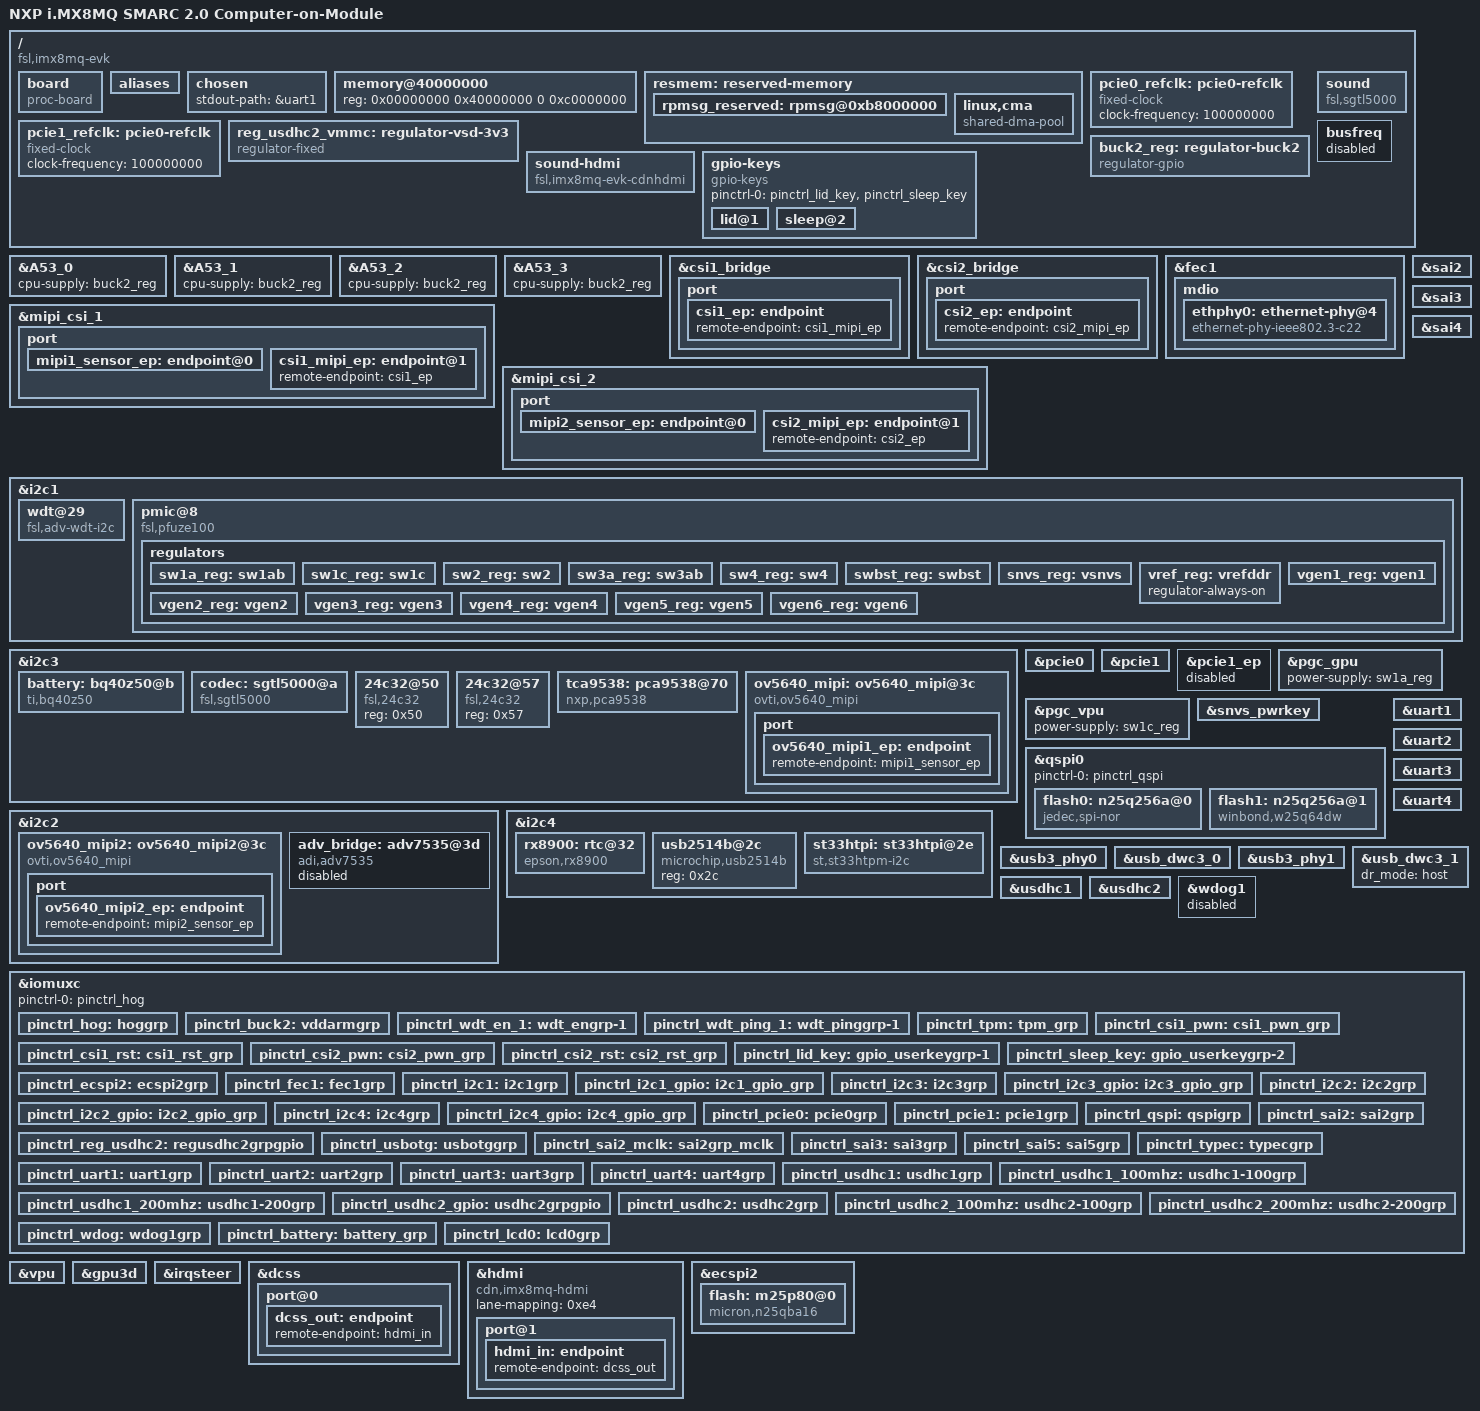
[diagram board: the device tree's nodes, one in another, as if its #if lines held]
// SPDX-License-Identifier: (GPL-2.0 OR MIT)
/*
 * Copyright 2017 NXP
 * Copyright (C) 2017-2018 Pengutronix, Lucas Stach <kernel@pengutronix.de>
 */

/dts-v1/;

//#define ENABLE_2ND_QSPI

#include <dt-bindings/usb/pd.h>
#include "imx8mq.dtsi"

/ {
	model = "NXP i.MX8MQ SMARC 2.0 Computer-on-Module";
	compatible = "fsl,imx8mq-evk", "fsl,imx8mq";

	board {
		compatible = "proc-board";
		board-type = "ROM-5720 A1";
		board-cpu = "IMX8MQ";
	};

	aliases {
		rtc0 = &rx8900;
		rtc1 = &snvs_rtc;
		sai0 = &sai1;
		sai1 = &sai2;
		sai2 = &sai3;
		sai3 = &sai4;
	};

	chosen {
		stdout-path = &uart1;
	};

	memory@40000000 {
		device_type = "memory";
		reg = <0x00000000 0x40000000 0 0xc0000000>;
	};

	reserved-memory {
		#address-cells = <2>;
		#size-cells = <2>;
		ranges;

		rpmsg_reserved: rpmsg@0xb8000000 {
			no-map;
			reg = <0 0xb8000000 0 0x400000>;
		};
	};



	resmem: reserved-memory {
		#address-cells = <2>;
		#size-cells = <2>;
		ranges;

		/* global autoconfigured region for contiguous allocations */
		linux,cma {
			compatible = "shared-dma-pool";
			reusable;
			size = <0 0x3c000000>;
			alloc-ranges = <0 0x40000000 0 0x40000000>;
			linux,cma-default;
		};
	};

	pcie0_refclk: pcie0-refclk {
		compatible = "fixed-clock";
		#clock-cells = <0>;
		clock-frequency = <100000000>;
	};

	pcie1_refclk: pcie0-refclk {
		compatible = "fixed-clock";
		#clock-cells = <0>;
		clock-frequency = <100000000>;
	};


	reg_usdhc2_vmmc: regulator-vsd-3v3 {
		pinctrl-names = "default";
		pinctrl-0 = <&pinctrl_reg_usdhc2>;
		compatible = "regulator-fixed";
		regulator-name = "VSD_3V3";
		regulator-min-microvolt = <3300000>;
		regulator-max-microvolt = <3300000>;
		gpio = <&gpio2 19 GPIO_ACTIVE_HIGH>;
		off-on-delay-us = <20000>;
		enable-active-high;
	};

	buck2_reg: regulator-buck2 {
		pinctrl-names = "default";
		pinctrl-0 = <&pinctrl_buck2>;
		compatible = "regulator-gpio";
		regulator-name = "vdd_arm";
		regulator-min-microvolt = <900000>;
		regulator-max-microvolt = <1000000>;
		gpios = <&gpio1 13 GPIO_ACTIVE_HIGH>;
		states = <1000000 0x0
			  900000 0x1>;
	};

        sound {
                compatible = "fsl,sgtl5000",
                             "fsl,imx-audio-sgtl5000";
                model = "sgtl5000";
                codec-master;
                ssi-controller = <&sai2>;
                audio-codec = <&codec>;
                audio-routing =
                        "MIC_IN", "Mic Jack",
                        "Mic Jack", "Mic Bias",
                        "Headphone Jack", "HP_OUT";
                no-audmux;
        };

	sound-hdmi {
		compatible = "fsl,imx8mq-evk-cdnhdmi",
				"fsl,imx-audio-cdnhdmi";
		model = "imx-audio-hdmi";
		audio-cpu = <&sai4>;
		protocol = <1>;
		hdmi-out;
		constraint-rate = <44100>,
				<88200>,
				<176400>,
				<32000>,
				<48000>,
				<96000>,
				<192000>;
	};

	gpio-keys {
                compatible = "gpio-keys";
                #address-cells = <1>;
                #size-cells = <0>;
                pinctrl-0 = <&pinctrl_lid_key &pinctrl_sleep_key>;
                pinctrl-names = "default";
                lid@1 {
			label = "LID KEY";
			gpios = <&gpio3 20 0>; /* GPIO_ACTIVE_LOW:1 */
			linux,input-type = <1>; /* EV_KEY */
			linux,code = <116>;     /* KEY_POWER */
			wakeup-source;
			debounce-interval = <100>;
                };
                sleep@2 {
			label = "SLEEP KEY";
			gpios = <&gpio3 25 0>; /* GPIO_ACTIVE_LOW:1 */
			linux,input-type = <1>; /* EV_KEY */
			linux,code = <116>;     /* KEY_POWER */
			wakeup-source;
			debounce-interval = <100>;
                };
	};

        busfreq {
                status = "disabled";
        };

};



&A53_0 {
	cpu-supply = <&buck2_reg>;
};

&A53_1 {
	cpu-supply = <&buck2_reg>;
};

&A53_2 {
	cpu-supply = <&buck2_reg>;
};

&A53_3 {
	cpu-supply = <&buck2_reg>;
};

&csi1_bridge {
	fsl,mipi-mode;
	fsl,two-8bit-sensor-mode;
	status = "okay";

	port {
		csi1_ep: endpoint {
			remote-endpoint = <&csi1_mipi_ep>;
		};
	};
};

&csi2_bridge {
	fsl,mipi-mode;
	fsl,two-8bit-sensor-mode;
	status = "okay";

	port {
		csi2_ep: endpoint {
			remote-endpoint = <&csi2_mipi_ep>;
		};
	};
};

&fec1 {
	pinctrl-names = "default";
	pinctrl-0 = <&pinctrl_fec1>;
	phy-mode = "rgmii-id";
	phy-handle = <&ethphy0>;
	fsl,magic-packet;
	status = "okay";

	mdio {
		#address-cells = <1>;
		#size-cells = <0>;

		ethphy0: ethernet-phy@4 {
			compatible = "ethernet-phy-ieee802.3-c22";
			reg = <4>;
			at803x,eee-disabled;
		};
	};
};

&mipi_csi_1 {
	#address-cells = <1>;
	#size-cells = <0>;
	status = "okay";
	port {
		mipi1_sensor_ep: endpoint@0 {
			remote-endpoint = <&ov5640_mipi1_ep>;
			data-lanes = <1 2>;
			bus-type = <4>;
		};

		csi1_mipi_ep: endpoint@1 {
			remote-endpoint = <&csi1_ep>;
		};
	};
};

&mipi_csi_2 {
	#address-cells = <1>;
	#size-cells = <0>;
	status = "okay";
	port {
		mipi2_sensor_ep: endpoint@0 {
			remote-endpoint = <&ov5640_mipi2_ep>;
			data-lanes = <1 2>;
			bus-type = <4>;
		};

		csi2_mipi_ep: endpoint@1 {
			remote-endpoint = <&csi2_ep>;
		};
	};
};

&sai2 {
	pinctrl-names = "default";
	pinctrl-0 = <&pinctrl_sai2>;
	assigned-clocks = <&clk IMX8MQ_CLK_SAI2>;
	assigned-clock-parents = <&clk IMX8MQ_AUDIO_PLL1_OUT>;
	assigned-clock-rates = <24576000>;
	status = "okay";
};

&sai3 {
	#sound-dai-cells = <0>;
	pinctrl-names = "default";
	pinctrl-0 = <&pinctrl_sai3>;
	assigned-clocks = <&clk IMX8MQ_CLK_SAI3>;
	assigned-clock-parents = <&clk IMX8MQ_AUDIO_PLL1_OUT>;
	assigned-clock-rates = <24576000>;
	status = "okay";
};

&sai4 {
	assigned-clocks = <&clk IMX8MQ_CLK_SAI4>;
	assigned-clock-parents = <&clk IMX8MQ_AUDIO_PLL1_OUT>;
	assigned-clock-rates = <24576000>;
	clocks = <&clk IMX8MQ_CLK_SAI4_IPG>, <&clk IMX8MQ_CLK_DUMMY>,
		<&clk IMX8MQ_CLK_SAI4_ROOT>, <&clk IMX8MQ_CLK_DUMMY>,
		<&clk IMX8MQ_CLK_DUMMY>, <&clk IMX8MQ_AUDIO_PLL1_OUT>,
		<&clk IMX8MQ_AUDIO_PLL2_OUT>;
	clock-names = "bus", "mclk0", "mclk1", "mclk2", "mclk3", "pll8k", "pll11k";
	status = "okay";
};

&i2c1 {
	clock-frequency = <400000>;
	pinctrl-names = "default";
	pinctrl-0 = <&pinctrl_i2c1>;
	pinctrl-1 = <&pinctrl_i2c1_gpio>;
        scl-gpios = <&gpio5 14 GPIO_ACTIVE_HIGH>;
        sda-gpios = <&gpio5 15 GPIO_ACTIVE_HIGH>;
	status = "okay";

	wdt@29 {
                compatible = "fsl,adv-wdt-i2c";
                pinctrl-names = "default";
                pinctrl-0 = <&pinctrl_wdt_en_1 &pinctrl_wdt_ping_1>;
                status = "okay";
                wdt-en = <&gpio3 18 0>;
                wdt-ping = <&gpio4 22 0>;
                reg = <0x29>;
        };

	pmic@8 {
		compatible = "fsl,pfuze100";
		fsl,pfuze-support-disable-sw;
		reg = <0x8>;

		regulators {
			sw1a_reg: sw1ab {
				regulator-min-microvolt = <825000>;
				regulator-max-microvolt = <1100000>;
			};

			sw1c_reg: sw1c {
				regulator-min-microvolt = <825000>;
				regulator-max-microvolt = <1100000>;
			};

			sw2_reg: sw2 {
				regulator-min-microvolt = <1100000>;
				regulator-max-microvolt = <1100000>;
				regulator-always-on;
			};

			sw3a_reg: sw3ab {
				regulator-min-microvolt = <825000>;
				regulator-max-microvolt = <1100000>;
				regulator-always-on;
			};

			sw4_reg: sw4 {
				regulator-min-microvolt = <1800000>;
				regulator-max-microvolt = <1800000>;
				regulator-always-on;
			};

			swbst_reg: swbst {
				regulator-min-microvolt = <5000000>;
				regulator-max-microvolt = <5150000>;
			};

			snvs_reg: vsnvs {
				regulator-min-microvolt = <1000000>;
				regulator-max-microvolt = <3000000>;
				regulator-always-on;
			};

			vref_reg: vrefddr {
				regulator-always-on;
			};

			vgen1_reg: vgen1 {
				regulator-min-microvolt = <800000>;
				regulator-max-microvolt = <1550000>;
			};

			vgen2_reg: vgen2 {
				regulator-min-microvolt = <850000>;
				regulator-max-microvolt = <975000>;
				regulator-always-on;
			};

			vgen3_reg: vgen3 {
				regulator-min-microvolt = <1675000>;
				regulator-max-microvolt = <1975000>;
				regulator-always-on;
			};

			vgen4_reg: vgen4 {
				regulator-min-microvolt = <1625000>;
				regulator-max-microvolt = <1875000>;
				regulator-always-on;
			};

			vgen5_reg: vgen5 {
				regulator-min-microvolt = <3075000>;
				regulator-max-microvolt = <3625000>;
				regulator-always-on;
			};

			vgen6_reg: vgen6 {
				regulator-min-microvolt = <1800000>;
				regulator-max-microvolt = <3300000>;
			};
		};
	};

};

&i2c3 {
	clock-frequency = <100000>;
	pinctrl-names = "default";
	pinctrl-0 = <&pinctrl_i2c3>;
	pinctrl-1 = <&pinctrl_i2c3_gpio>;
        scl-gpios = <&gpio5 18 GPIO_ACTIVE_HIGH>;
        sda-gpios = <&gpio5 19 GPIO_ACTIVE_HIGH>;
	status = "okay";

        battery: bq40z50@b {
                compatible = "ti,bq40z50";
                reg = <0x0b>;
                pinctrl-names = "default";
                pinctrl-0 = <&pinctrl_battery>;
        };

	codec: sgtl5000@a {
		compatible = "fsl,sgtl5000";
		reg = <0x0a>;
                clocks = <&clk IMX8MQ_CLK_SAI2_ROOT>;
		clock-names = "mclk";
		pinctrl-names = "default";
                pinctrl-0 = <&pinctrl_sai2_mclk>;

	};
        24c32@50 {
                compatible = "fsl,24c32";
                reg = <0x50>;
        };
	
        24c32@57 {
                compatible = "fsl,24c32";
                reg = <0x57>;
        };
	tca9538: pca9538@70 {
		compatible = "nxp,pca9538";
		reg = <0x70>;
		#gpio-cells = <2>;
		gpio-controller;
	};
	ov5640_mipi: ov5640_mipi@3c {
                compatible = "ovti,ov5640_mipi";
                reg = <0x3c>;
                status = "okay";
                pinctrl-names = "default";
                pinctrl-0 = <&pinctrl_csi1_pwn>, <&pinctrl_csi1_rst>;
                clocks = <&clk IMX8MQ_CLK_CLKO1>;
                clock-names = "csi_mclk";
                assigned-clocks = <&clk IMX8MQ_CLK_CLKO1>;
                assigned-clock-parents = <&clk IMX8MQ_SYS2_PLL_200M>;
		assigned-clock-rates = <20000000>;                
                csi_id = <0>;
                pwn-gpios = <&gpio1 3 GPIO_ACTIVE_HIGH>;
                rst-gpios = <&gpio4 29 GPIO_ACTIVE_LOW>;
		mclk = <20000000>;
		mclk_source = <0>;
                port {
                        ov5640_mipi1_ep: endpoint {
                                remote-endpoint = <&mipi1_sensor_ep>;
                        };
                };
        };

};

&i2c2 {
	clock-frequency = <100000>;
	pinctrl-names = "default";
	pinctrl-0 = <&pinctrl_i2c2>;
        pinctrl-1 = <&pinctrl_i2c2_gpio>;
        scl-gpios = <&gpio5 16 GPIO_ACTIVE_HIGH>;
        sda-gpios = <&gpio5 17 GPIO_ACTIVE_HIGH>;
	status = "okay";

	ov5640_mipi2: ov5640_mipi2@3c {
		compatible = "ovti,ov5640_mipi";
		reg = <0x3c>;
		status = "okay";
		pinctrl-names = "default";
		pinctrl-0 = <&pinctrl_csi2_pwn>, <&pinctrl_csi2_rst>;
		clocks = <&clk IMX8MQ_CLK_CLKO1>;
		clock-names = "csi_mclk";
		assigned-clocks = <&clk IMX8MQ_CLK_CLKO1>;
		assigned-clock-parents = <&clk IMX8MQ_SYS2_PLL_200M>;
		assigned-clock-rates = <0>, <20000000>;  
		csi_id = <1>;
                pwn-gpios = <&gpio1 5 GPIO_ACTIVE_HIGH>;
                rst-gpios = <&gpio1 6 GPIO_ACTIVE_LOW>;
		mclk = <20000000>;
		mclk_source = <0>;
		port {
			ov5640_mipi2_ep: endpoint {
				remote-endpoint = <&mipi2_sensor_ep>;
			};
		};
	};
        adv_bridge: adv7535@3d {
                compatible = "adi,adv7535";
                reg = <0x3d>;
                pinctrl-names = "default";
                pinctrl-0 = <&pinctrl_lcd0>;
		pd-gpios = <&gpio5 6 1>;
                adi,addr-cec = <0x3b>;
                adi,dsi-lanes = <4>;
                interrupt-parent = <&gpio5>;
                interrupts = <7 IRQ_TYPE_LEVEL_LOW>;
                status = "disabled";
        };

};

&i2c4 {
	clock-frequency = <100000>;
        pinctrl-names = "default", "gpio";
        pinctrl-0 = <&pinctrl_i2c4>;
        pinctrl-1 = <&pinctrl_i2c4_gpio>;
        scl-gpios = <&gpio5 20 GPIO_ACTIVE_HIGH>;
        sda-gpios = <&gpio5 21 GPIO_ACTIVE_HIGH>;
	status = "okay";

	rx8900: rtc@32 {
		compatible = "epson,rx8900";
		reg = <0x32>;
                epson,vdet-disable;
                trickle-diode-disable;
	};


        usb2514b@2c {
                compatible = "microchip,usb2514b";
                reg = <0x2c>;
        };
	
	st33htpi: st33htpi@2e{
		compatible = "st,st33htpm-i2c";
		reg= <0x2e>;
		pinctrl-names = "default";
                pinctrl-0 = <&pinctrl_tpm>;
                interrupt-parent = <&gpio5>;
                interrupts = <5 IRQ_TYPE_LEVEL_HIGH>;
	};

};

&pcie0 {
	pinctrl-names = "default";
	pinctrl-0 = <&pinctrl_pcie0>;
        reset-gpio = <&gpio4 11 GPIO_ACTIVE_LOW>;
	clocks = <&clk IMX8MQ_CLK_PCIE1_ROOT>,
		 <&clk IMX8MQ_CLK_PCIE1_AUX>,
		 <&clk IMX8MQ_CLK_PCIE1_PHY>,
		 <&pcie0_refclk>;
	clock-names = "pcie", "pcie_aux", "pcie_phy", "pcie_bus";
	ext_osc = <1>;
	status = "okay";
};

&pcie1 {
	pinctrl-names = "default";
	pinctrl-0 = <&pinctrl_pcie1>;
	reset-gpio = <&gpio4 10 GPIO_ACTIVE_LOW>;
	clocks = <&clk IMX8MQ_CLK_PCIE2_ROOT>,
		 <&clk IMX8MQ_CLK_PCIE2_AUX>,
		 <&clk IMX8MQ_CLK_PCIE2_PHY>,
		 <&pcie1_refclk>;
	clock-names = "pcie", "pcie_aux", "pcie_phy", "pcie_bus";
	reset-gpio = <&gpio4 10 GPIO_ACTIVE_LOW>;
	//disable-gpio = <&tca9538 0 GPIO_ACTIVE_LOW>; //W_DISABLE1
	status = "okay";
};

&pcie1_ep {
	pinctrl-names = "default";
	pinctrl-0 = <&pinctrl_pcie1>;
	clocks = <&clk IMX8MQ_CLK_PCIE2_ROOT>,
		 <&clk IMX8MQ_CLK_PCIE2_AUX>,
		 <&clk IMX8MQ_CLK_PCIE2_PHY>,
		 <&pcie1_refclk>;
	clock-names = "pcie", "pcie_aux", "pcie_phy", "pcie_bus";
	status = "disabled";
};

&pgc_gpu {
	power-supply = <&sw1a_reg>;
};

&pgc_vpu {
	power-supply = <&sw1c_reg>;
};

&snvs_pwrkey {
	status = "okay";
};

&qspi0 {
	pinctrl-names = "default";
	pinctrl-0 = <&pinctrl_qspi>;
	status = "okay";
/*
        fsl,qspi-has-second-chip = <1>;
*/
//        ddrsmp=<0>;
	flash0: n25q256a@0 {
		reg = <0>;
		#address-cells = <1>;
		#size-cells = <1>;
		compatible = "jedec,spi-nor";
		spi-max-frequency = <29000000>;
		spi-tx-bus-width = <4>;
		spi-rx-bus-width = <4>;
		spi-nor,ddr-quad-read-dummy = <6>;
	};
#ifdef ENABLE_2ND_QSPI
	flash1: n25q256a@1 {
		reg = <1>;
		#address-cells = <1>;
		#size-cells = <1>;
		compatible = "winbond,w25q64dw";
		spi-max-frequency = <29000000>;
		spi-nor,ddr-quad-read-dummy = <6>;
	};
#endif
};

&uart1 {
	pinctrl-names = "default";
	pinctrl-0 = <&pinctrl_uart1>;
	assigned-clocks = <&clk IMX8MQ_CLK_UART1>;
	assigned-clock-parents = <&clk IMX8MQ_CLK_25M>;
	status = "okay";
};

&uart2 {
	pinctrl-names = "default";
	pinctrl-0 = <&pinctrl_uart2>;
	assigned-clocks = <&clk IMX8MQ_CLK_UART2>;
	assigned-clock-parents = <&clk IMX8MQ_CLK_25M>;
	status = "okay";
};

&uart3 { /* BT */
	pinctrl-names = "default";
	pinctrl-0 = <&pinctrl_uart3>;
	assigned-clocks = <&clk IMX8MQ_CLK_UART3>;
	assigned-clock-parents = <&clk IMX8MQ_CLK_25M>;
	fsl,uart-has-rtscts;
	status = "okay";
};

&uart4 {
	pinctrl-names = "default";
	pinctrl-0 = <&pinctrl_uart4>;
	assigned-clocks = <&clk IMX8MQ_CLK_UART4>;
	assigned-clock-parents = <&clk IMX8MQ_CLK_25M>;
	status = "okay";
};

&usb3_phy0 {
	status = "okay";
};

&usb_dwc3_0 {
	pinctrl-names = "default";
	pinctrl-0 = <&pinctrl_usbotg>;
	dr_mode = "host";

	status = "okay";
};

&usb3_phy1 {
	status = "okay";
};

&usb_dwc3_1 {
	dr_mode = "host";
	status = "okay";
};

&usdhc1 {
	pinctrl-names = "default";
	pinctrl-0 = <&pinctrl_usdhc1>;
	vqmmc-supply = <&sw4_reg>;
	bus-width = <8>;
	non-removable;
	no-sd;
	no-sdio;
	status = "okay";
};

&usdhc2 {
	pinctrl-names = "default";
	pinctrl-0 = <&pinctrl_usdhc2>, <&pinctrl_usdhc2_gpio>;
	cd-gpios = <&gpio2 12 GPIO_ACTIVE_LOW>;
	wp-gpios = <&gpio2 20 GPIO_ACTIVE_HIGH>;
	vmmc-supply = <&reg_usdhc2_vmmc>;
	status = "okay";
};

&wdog1 {
	pinctrl-names = "default";
	pinctrl-0 = <&pinctrl_wdog>;
	fsl,ext-reset-output;
	status = "disabled";
};

&iomuxc {
	pinctrl-names = "default";
	pinctrl-0 = <&pinctrl_hog>;

	pinctrl_hog: hoggrp {
		fsl,pins = <
			MX8MQ_IOMUXC_GPIO1_IO00_GPIO1_IO0		0x19	/* GPIO4 */
			MX8MQ_IOMUXC_SPDIF_RX_GPIO5_IO4			0x19	/* GPIO5 */
			MX8MQ_IOMUXC_SAI5_RXFS_GPIO3_IO19		0x19	/* GPIO6 */
			MX8MQ_IOMUXC_SAI5_RXD0_GPIO3_IO21		0x19	/* GPIO7 */
			MX8MQ_IOMUXC_GPIO1_IO08_GPIO1_IO8		0x19	/* GPIO8 */
			MX8MQ_IOMUXC_SAI5_RXD2_GPIO3_IO23		0x19	/* GPIO9 */
			MX8MQ_IOMUXC_SAI3_RXFS_GPIO4_IO28		0x19	/* GPIO10 */	
			MX8MQ_IOMUXC_SAI1_RXFS_GPIO4_IO0		0x19	/* GPIO11 */
			MX8MQ_IOMUXC_GPIO1_IO12_GPIO1_IO12		0x19	/* USB1_OTG_VBUS */
			MX8MQ_IOMUXC_GPIO1_IO14_CCMSRCGPCMIX_CLKO1	0x59	/* CAM_MCK */
			MX8MQ_IOMUXC_SAI5_RXD1_GPIO3_IO22		0x19	/* TEST */
			MX8MQ_IOMUXC_SAI1_MCLK_GPIO4_IO20		0x19	/* UART_DBG_SEL */
			MX8MQ_IOMUXC_NAND_CE1_B_GPIO3_IO2		0x19	/* RESET_DELAY */
		>;
	};

	pinctrl_buck2: vddarmgrp {
		fsl,pins = <
			MX8MQ_IOMUXC_GPIO1_IO13_GPIO1_IO13		0x19
		>;

	};


	pinctrl_wdt_en_1: wdt_engrp-1 {
		fsl,pins = <
			MX8MQ_IOMUXC_NAND_WP_B_GPIO3_IO18		0x19	/* WDT_EN */
		>;
	};
	pinctrl_wdt_ping_1: wdt_pinggrp-1 {
		fsl,pins = <
			MX8MQ_IOMUXC_SAI2_RXC_GPIO4_IO22		0x19	/* WDOG_TRIG */
			>;
	};

	pinctrl_tpm: tpm_grp {
		fsl,pins = <
			MX8MQ_IOMUXC_SAI1_RXC_GPIO4_IO1			0x19	/* TPM_RESET */
			MX8MQ_IOMUXC_SPDIF_EXT_CLK_GPIO5_IO5		0x19	/* TPM_IRQ */
		>;
	};

	pinctrl_csi1_pwn: csi1_pwn_grp {
		fsl,pins = <
			MX8MQ_IOMUXC_GPIO1_IO03_GPIO1_IO3		0x19	/* GPIO0 or CAM0_PWR*/
		>;
	};

        pinctrl_csi1_rst: csi1_rst_grp {
                fsl,pins = <
			MX8MQ_IOMUXC_SAI3_RXC_GPIO4_IO29		0x19	/* GPIO2 or CAM0_RST*/
                >;
        };

	pinctrl_csi2_pwn: csi2_pwn_grp {
		fsl,pins = <
			MX8MQ_IOMUXC_GPIO1_IO05_GPIO1_IO5               0x19	/* GPIO1 or CAM1_PWR*/
		>;
	};

        pinctrl_csi2_rst: csi2_rst_grp {
                fsl,pins = <
                        MX8MQ_IOMUXC_GPIO1_IO06_GPIO1_IO6               0x19	/* GPIO3 or CAM1_RST*/
                >;
        };

	pinctrl_lid_key: gpio_userkeygrp-1 {
		fsl,pins = <
			MX8MQ_IOMUXC_SAI5_RXC_GPIO3_IO20		0x59	/* LID */
		>;
	};
	pinctrl_sleep_key: gpio_userkeygrp-2 {
		fsl,pins = <
			MX8MQ_IOMUXC_SAI5_MCLK_GPIO3_IO25		0x59	/* SLEEP */	
		>;
	};

        pinctrl_ecspi2: ecspi2grp {
                fsl,pins = <
			MX8MQ_IOMUXC_ECSPI2_SS0_GPIO5_IO13		0x19	/* SPI0_CS0 */
			MX8MQ_IOMUXC_ECSPI2_MOSI_ECSPI2_MOSI		0x82	/* SPI0_DO */
			MX8MQ_IOMUXC_ECSPI2_MISO_ECSPI2_MISO		0x82	/* SPI0_DIN */
			MX8MQ_IOMUXC_ECSPI2_SCLK_ECSPI2_SCLK		0x82	/* SPI0_CK */
                >;
        };

	pinctrl_fec1: fec1grp {
		fsl,pins = <
			MX8MQ_IOMUXC_ENET_MDC_ENET1_MDC			0x3
			MX8MQ_IOMUXC_ENET_MDIO_ENET1_MDIO		0x23
			MX8MQ_IOMUXC_ENET_TD3_ENET1_RGMII_TD3		0x1f
			MX8MQ_IOMUXC_ENET_TD2_ENET1_RGMII_TD2		0x1f
			MX8MQ_IOMUXC_ENET_TD1_ENET1_RGMII_TD1		0x1f
			MX8MQ_IOMUXC_ENET_TD0_ENET1_RGMII_TD0		0x1f
			MX8MQ_IOMUXC_ENET_RD3_ENET1_RGMII_RD3		0x91
			MX8MQ_IOMUXC_ENET_RD2_ENET1_RGMII_RD2		0x91
			MX8MQ_IOMUXC_ENET_RD1_ENET1_RGMII_RD1		0x91
			MX8MQ_IOMUXC_ENET_RD0_ENET1_RGMII_RD0		0x91
			MX8MQ_IOMUXC_ENET_TXC_ENET1_RGMII_TXC		0x1f
			MX8MQ_IOMUXC_ENET_RXC_ENET1_RGMII_RXC		0x91
			MX8MQ_IOMUXC_ENET_RX_CTL_ENET1_RGMII_RX_CTL	0x91
			MX8MQ_IOMUXC_ENET_TX_CTL_ENET1_RGMII_TX_CTL	0x1f
			MX8MQ_IOMUXC_GPIO1_IO09_GPIO1_IO9		0x19
		>;
	};

	pinctrl_i2c1: i2c1grp {
		fsl,pins = <
			MX8MQ_IOMUXC_I2C1_SCL_I2C1_SCL			0x4000007f
			MX8MQ_IOMUXC_I2C1_SDA_I2C1_SDA			0x4000007f
		>;
	};

        pinctrl_i2c1_gpio: i2c1_gpio_grp {
                fsl,pins = <
                        MX8MQ_IOMUXC_I2C1_SCL_GPIO5_IO14                0x19
                        MX8MQ_IOMUXC_I2C1_SDA_GPIO5_IO15                0x19
                >;
        };

	pinctrl_i2c3: i2c3grp {
		fsl,pins = <
			MX8MQ_IOMUXC_I2C3_SCL_I2C3_SCL			0x4000007f
			MX8MQ_IOMUXC_I2C3_SDA_I2C3_SDA			0x4000007f
		>;
	};

        pinctrl_i2c3_gpio: i2c3_gpio_grp {
                fsl,pins = <
                        MX8MQ_IOMUXC_I2C3_SCL_GPIO5_IO18                0x19
                        MX8MQ_IOMUXC_I2C3_SDA_GPIO5_IO19                0x19
                >;
        };

	pinctrl_i2c2: i2c2grp {
		fsl,pins = <
			MX8MQ_IOMUXC_I2C2_SCL_I2C2_SCL			0x40000067
			MX8MQ_IOMUXC_I2C2_SDA_I2C2_SDA			0x40000067
		>;
	};

        pinctrl_i2c2_gpio: i2c2_gpio_grp {
                fsl,pins = <
                        MX8MQ_IOMUXC_I2C2_SCL_GPIO5_IO16                0x19
                        MX8MQ_IOMUXC_I2C2_SDA_GPIO5_IO17                0x19
                >;
        };

	pinctrl_i2c4: i2c4grp {
		fsl,pins = <
			MX8MQ_IOMUXC_I2C4_SCL_I2C4_SCL			0x40000067
			MX8MQ_IOMUXC_I2C4_SDA_I2C4_SDA			0x40000067
		>;
	};

        pinctrl_i2c4_gpio: i2c4_gpio_grp {
                fsl,pins = <
                        MX8MQ_IOMUXC_I2C4_SCL_GPIO5_IO20                0x19
                        MX8MQ_IOMUXC_I2C4_SDA_GPIO5_IO21                0x19
                >;
        };

        pinctrl_pcie0: pcie0grp {
                fsl,pins = <
                        MX8MQ_IOMUXC_SAI1_TXC_GPIO4_IO11	0x16	/* PCIE_B_RST */
                >;
        };


        pinctrl_pcie1: pcie1grp {
                fsl,pins = <
                        MX8MQ_IOMUXC_SAI1_TXFS_GPIO4_IO10       0x16	/* PCIE_A_RST */
                >;
        };


	pinctrl_qspi: qspigrp {
		fsl,pins = <
			MX8MQ_IOMUXC_NAND_ALE_QSPI_A_SCLK	0x82
			MX8MQ_IOMUXC_NAND_CE0_B_QSPI_A_SS0_B	0x82
			MX8MQ_IOMUXC_NAND_DATA00_QSPI_A_DATA0	0x82
			MX8MQ_IOMUXC_NAND_DATA01_QSPI_A_DATA1	0x82
			MX8MQ_IOMUXC_NAND_DATA02_QSPI_A_DATA2	0x82
			MX8MQ_IOMUXC_NAND_DATA03_QSPI_A_DATA3	0x82
#ifdef ENABLE_2ND_QSPI
                        MX8MQ_IOMUXC_NAND_CLE_QSPI_B_SCLK       0x82
			MX8MQ_IOMUXC_NAND_CE3_B_QSPI_B_SS1_B	0x82 
                        MX8MQ_IOMUXC_NAND_CE2_B_QSPI_B_SS0_B    0x82
                        MX8MQ_IOMUXC_NAND_DATA04_QSPI_B_DATA0   0x82
                        MX8MQ_IOMUXC_NAND_DATA05_QSPI_B_DATA1   0x82
                        MX8MQ_IOMUXC_NAND_DATA06_QSPI_B_DATA2   0x82
                        MX8MQ_IOMUXC_NAND_DATA07_QSPI_B_DATA3   0x82
#endif
		>;
	};

	pinctrl_reg_usdhc2: regusdhc2grpgpio {
		fsl,pins = <
			MX8MQ_IOMUXC_SD2_RESET_B_GPIO2_IO19		0x41
		>;
	};

        pinctrl_usbotg: usbotggrp {
                fsl,pins = <
			MX8MQ_IOMUXC_GPIO1_IO10_GPIO1_IO10	0x19	/* USB0_OTG_ID_1V8*/
			MX8MQ_IOMUXC_SAI2_RXFS_GPIO4_IO21	0x16	/* USB_OTG0_OC */
                >;
        };

	pinctrl_sai2: sai2grp {
		fsl,pins = <
			MX8MQ_IOMUXC_SAI2_TXFS_SAI2_TX_SYNC	0xd6	/* I2S0_LRCK */
			MX8MQ_IOMUXC_SAI2_TXC_SAI2_TX_BCLK	0xd6	/* I2S0_CK */
			MX8MQ_IOMUXC_SAI2_RXD0_SAI2_RX_DATA0	0xd6	/* I2S0_SDIN */
			MX8MQ_IOMUXC_SAI2_TXD0_SAI2_TX_DATA0	0xd6	/* I2S0_SDOUT */
		>;
	};

        pinctrl_sai2_mclk: sai2grp_mclk {
                fsl,pins = <
			MX8MQ_IOMUXC_SAI2_MCLK_SAI2_MCLK        0xd6	/* AUDIO_MCK */
                >;
        };
	
	pinctrl_sai3: sai3grp {
		fsl,pins = <
			MX8MQ_IOMUXC_SAI3_TXFS_SAI3_TX_SYNC     0xd6
			MX8MQ_IOMUXC_SAI3_TXC_SAI3_TX_BCLK      0xd6
			MX8MQ_IOMUXC_SAI3_TXD_SAI3_TX_DATA0	0xd6
			MX8MQ_IOMUXC_SAI3_RXD_SAI3_RX_DATA0	0xd6
		>;
	};

	pinctrl_sai5: sai5grp {
		fsl,pins = <
			MX8MQ_IOMUXC_SAI5_MCLK_SAI5_MCLK	0xd6
			MX8MQ_IOMUXC_SAI5_RXC_SAI5_RX_BCLK	0xd6
			MX8MQ_IOMUXC_SAI5_RXFS_SAI5_RX_SYNC	0xd6
			MX8MQ_IOMUXC_SAI5_RXD0_SAI5_RX_DATA0	0xd6
			MX8MQ_IOMUXC_SAI5_RXD1_SAI5_RX_DATA1    0xd6
			MX8MQ_IOMUXC_SAI5_RXD2_SAI5_RX_DATA2    0xd6
			MX8MQ_IOMUXC_SAI5_RXD3_SAI5_RX_DATA3    0xd6
		>;
	};


	pinctrl_typec: typecgrp {
		fsl,pins = <
			MX8MQ_IOMUXC_NAND_CE2_B_GPIO3_IO3		0x17059
		>;
	};

	pinctrl_uart1: uart1grp {
		fsl,pins = <
			MX8MQ_IOMUXC_UART1_RXD_UART1_DCE_RX		0x49
			MX8MQ_IOMUXC_UART1_TXD_UART1_DCE_TX		0x49
		>;
	};

	pinctrl_uart2: uart2grp {
		fsl,pins = <
			MX8MQ_IOMUXC_UART2_RXD_UART2_DCE_RX		0x49
			MX8MQ_IOMUXC_UART2_TXD_UART2_DCE_TX		0x49
		>;
	};

	pinctrl_uart3: uart3grp {
		fsl,pins = <
			MX8MQ_IOMUXC_UART3_TXD_UART3_DCE_TX		0x49
			MX8MQ_IOMUXC_UART3_RXD_UART3_DCE_RX		0x49
			MX8MQ_IOMUXC_ECSPI1_MISO_UART3_DCE_CTS_B	0x49
			MX8MQ_IOMUXC_ECSPI1_SS0_UART3_DCE_RTS_B		0x49
		>;
	};

	pinctrl_uart4: uart4grp {
		fsl,pins = <
			MX8MQ_IOMUXC_UART4_RXD_UART4_DCE_RX		0x49
			MX8MQ_IOMUXC_UART4_TXD_UART4_DCE_TX		0x49
		>;
	};

	pinctrl_usdhc1: usdhc1grp {
		fsl,pins = <
			MX8MQ_IOMUXC_SD1_CLK_USDHC1_CLK			0x83
			MX8MQ_IOMUXC_SD1_CMD_USDHC1_CMD			0xc3
			MX8MQ_IOMUXC_SD1_DATA0_USDHC1_DATA0		0xc3
			MX8MQ_IOMUXC_SD1_DATA1_USDHC1_DATA1		0xc3
			MX8MQ_IOMUXC_SD1_DATA2_USDHC1_DATA2		0xc3
			MX8MQ_IOMUXC_SD1_DATA3_USDHC1_DATA3		0xc3
			MX8MQ_IOMUXC_SD1_DATA4_USDHC1_DATA4		0xc3
			MX8MQ_IOMUXC_SD1_DATA5_USDHC1_DATA5		0xc3
			MX8MQ_IOMUXC_SD1_DATA6_USDHC1_DATA6		0xc3
			MX8MQ_IOMUXC_SD1_DATA7_USDHC1_DATA7		0xc3
			MX8MQ_IOMUXC_SD1_STROBE_USDHC1_STROBE		0x83
			MX8MQ_IOMUXC_SD1_RESET_B_USDHC1_RESET_B		0xc1
		>;
	};

	pinctrl_usdhc1_100mhz: usdhc1-100grp {
		fsl,pins = <
			MX8MQ_IOMUXC_SD1_CLK_USDHC1_CLK			0x8d
			MX8MQ_IOMUXC_SD1_CMD_USDHC1_CMD			0xcd
			MX8MQ_IOMUXC_SD1_DATA0_USDHC1_DATA0		0xcd
			MX8MQ_IOMUXC_SD1_DATA1_USDHC1_DATA1		0xcd
			MX8MQ_IOMUXC_SD1_DATA2_USDHC1_DATA2		0xcd
			MX8MQ_IOMUXC_SD1_DATA3_USDHC1_DATA3		0xcd
			MX8MQ_IOMUXC_SD1_DATA4_USDHC1_DATA4		0xcd
			MX8MQ_IOMUXC_SD1_DATA5_USDHC1_DATA5		0xcd
			MX8MQ_IOMUXC_SD1_DATA6_USDHC1_DATA6		0xcd
			MX8MQ_IOMUXC_SD1_DATA7_USDHC1_DATA7		0xcd
			MX8MQ_IOMUXC_SD1_STROBE_USDHC1_STROBE		0x8d
			MX8MQ_IOMUXC_SD1_RESET_B_USDHC1_RESET_B		0xc1
		>;
	};

	pinctrl_usdhc1_200mhz: usdhc1-200grp {
		fsl,pins = <
			MX8MQ_IOMUXC_SD1_CLK_USDHC1_CLK			0x9f
			MX8MQ_IOMUXC_SD1_CMD_USDHC1_CMD			0xdf
			MX8MQ_IOMUXC_SD1_DATA0_USDHC1_DATA0		0xdf
			MX8MQ_IOMUXC_SD1_DATA1_USDHC1_DATA1		0xdf
			MX8MQ_IOMUXC_SD1_DATA2_USDHC1_DATA2		0xdf
			MX8MQ_IOMUXC_SD1_DATA3_USDHC1_DATA3		0xdf
			MX8MQ_IOMUXC_SD1_DATA4_USDHC1_DATA4		0xdf
			MX8MQ_IOMUXC_SD1_DATA5_USDHC1_DATA5		0xdf
			MX8MQ_IOMUXC_SD1_DATA6_USDHC1_DATA6		0xdf
			MX8MQ_IOMUXC_SD1_DATA7_USDHC1_DATA7		0xdf
			MX8MQ_IOMUXC_SD1_STROBE_USDHC1_STROBE		0x9f
			MX8MQ_IOMUXC_SD1_RESET_B_USDHC1_RESET_B		0xc1
		>;
	};

	pinctrl_usdhc2_gpio: usdhc2grpgpio {
		fsl,pins = <
			MX8MQ_IOMUXC_SD2_CD_B_GPIO2_IO12	0x41
			MX8MQ_IOMUXC_SD2_WP_GPIO2_IO20		0x41
		>;
	};

	pinctrl_usdhc2: usdhc2grp {
		fsl,pins = <
			MX8MQ_IOMUXC_SD2_CLK_USDHC2_CLK			0x83
			MX8MQ_IOMUXC_SD2_CMD_USDHC2_CMD			0xc3
			MX8MQ_IOMUXC_SD2_DATA0_USDHC2_DATA0		0xc3
			MX8MQ_IOMUXC_SD2_DATA1_USDHC2_DATA1		0xc3
			MX8MQ_IOMUXC_SD2_DATA2_USDHC2_DATA2		0xc3
			MX8MQ_IOMUXC_SD2_DATA3_USDHC2_DATA3		0xc3
			MX8MQ_IOMUXC_GPIO1_IO04_USDHC2_VSELECT		0xc1
		>;
	};

	pinctrl_usdhc2_100mhz: usdhc2-100grp {
		fsl,pins = <
			MX8MQ_IOMUXC_SD2_CLK_USDHC2_CLK			0x85
			MX8MQ_IOMUXC_SD2_CMD_USDHC2_CMD			0xc5
			MX8MQ_IOMUXC_SD2_DATA0_USDHC2_DATA0		0xc5
			MX8MQ_IOMUXC_SD2_DATA1_USDHC2_DATA1		0xc5
			MX8MQ_IOMUXC_SD2_DATA2_USDHC2_DATA2		0xc5
			MX8MQ_IOMUXC_SD2_DATA3_USDHC2_DATA3		0xc5
			MX8MQ_IOMUXC_GPIO1_IO04_USDHC2_VSELECT		0xc1
		>;
	};

	pinctrl_usdhc2_200mhz: usdhc2-200grp {
		fsl,pins = <
			MX8MQ_IOMUXC_SD2_CLK_USDHC2_CLK			0x87
			MX8MQ_IOMUXC_SD2_CMD_USDHC2_CMD			0xc7
			MX8MQ_IOMUXC_SD2_DATA0_USDHC2_DATA0		0xc7
			MX8MQ_IOMUXC_SD2_DATA1_USDHC2_DATA1		0xc7
			MX8MQ_IOMUXC_SD2_DATA2_USDHC2_DATA2		0xc7
			MX8MQ_IOMUXC_SD2_DATA3_USDHC2_DATA3		0xc7
			MX8MQ_IOMUXC_GPIO1_IO04_USDHC2_VSELECT		0xc1
		>;
	};

	pinctrl_wdog: wdog1grp {
		fsl,pins = <
			MX8MQ_IOMUXC_GPIO1_IO02_WDOG1_WDOG_B		0xc6
		>;
	};

        pinctrl_battery: battery_grp {
                fsl,pins = <
			MX8MQ_IOMUXC_NAND_READY_B_GPIO3_IO16		0x19	/* SMB_ALERT_1V8 */
			MX8MQ_IOMUXC_SAI5_RXD3_GPIO3_IO24		0x19	/* BATLOW */
			MX8MQ_IOMUXC_SAI3_MCLK_GPIO5_IO2		0x19	/* CHARGING */
			MX8MQ_IOMUXC_SPDIF_TX_GPIO5_IO3			0x19	/* CHARGER_PRSNT */
                >;
        };
	
	pinctrl_lcd0: lcd0grp {
		fsl,pins = <
			MX8MQ_IOMUXC_ECSPI1_SCLK_GPIO5_IO6	0x19		/* LCD0_VDD_EN */
			MX8MQ_IOMUXC_ECSPI1_MOSI_GPIO5_IO7	0x19		/* DSI0_TE */
		>;
	};

};

&vpu {
	status = "okay";
};

&gpu3d {
	status = "okay";
};

&irqsteer {
	status = "okay";
};

&dcss {
	status = "okay";

	port@0 {
		dcss_out: endpoint {
			  remote-endpoint = <&hdmi_in>;
		};
	};
};

&hdmi {
	compatible = "cdn,imx8mq-hdmi";
	lane-mapping = <0xe4>;
	status = "okay";
	port@1 {
		hdmi_in: endpoint {
			remote-endpoint = <&dcss_out>;
		};
	};
};

&ecspi2 {
        cs-gpios = <&gpio5 13 0>;
        pinctrl-names = "default";
        pinctrl-0 = <&pinctrl_ecspi2>;
        status = "okay";

        flash: m25p80@0 {
                #address-cells = <1>;
                #size-cells = <0>;
                compatible = "micron,n25qba16";
                spi-max-frequency = <20000000>;
                reg = <0>;
        };
};


